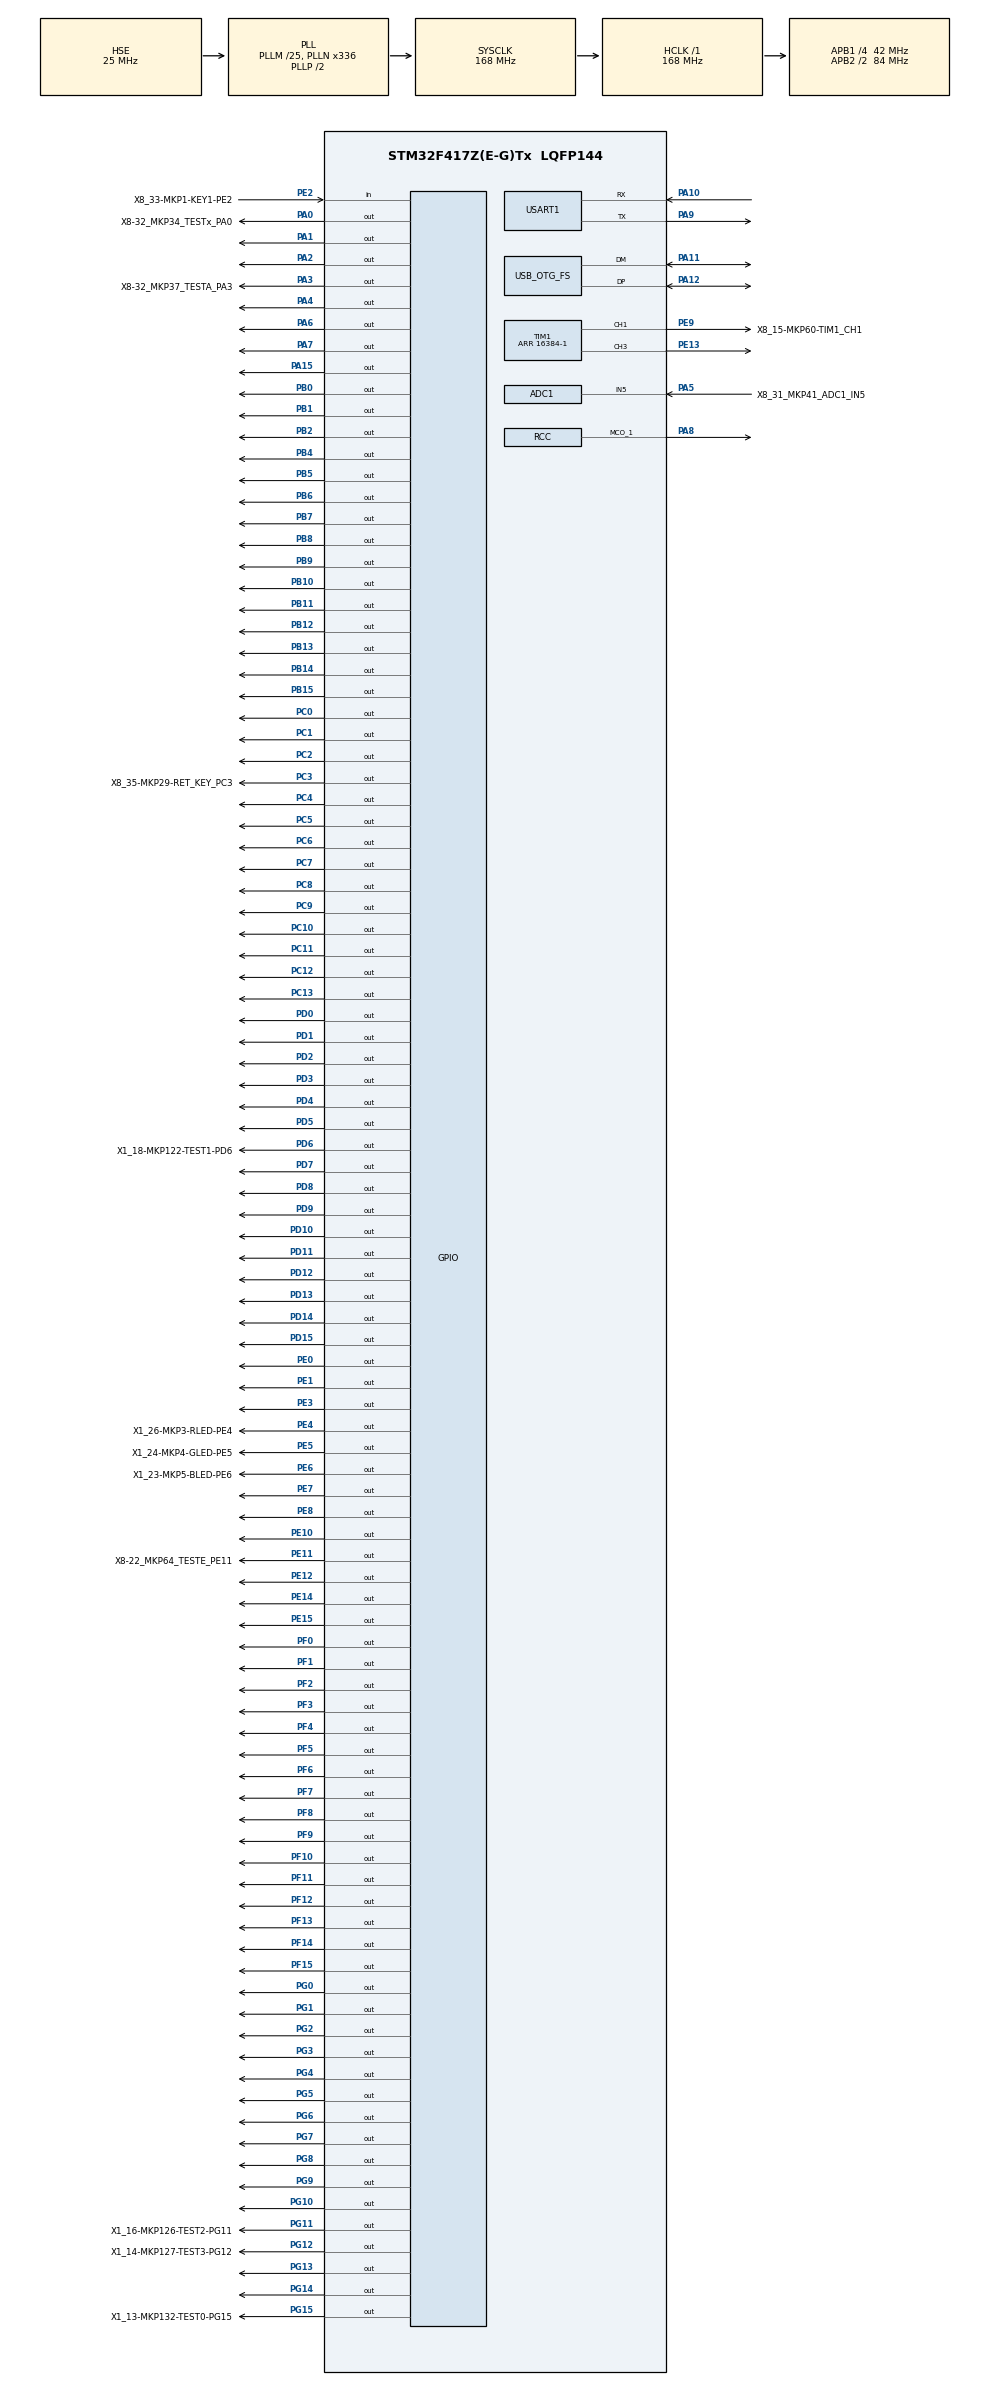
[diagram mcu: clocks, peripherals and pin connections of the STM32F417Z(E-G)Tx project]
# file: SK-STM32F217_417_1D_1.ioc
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ADC1.Channel-2\#ChannelRegularConversion=ADC_CHANNEL_5
ADC1.Channel-3\#ChannelRegularConversion=ADC_CHANNEL_VREFINT
ADC1.ClockPrescaler=ADC_CLOCK_SYNC_PCLK_DIV6
ADC1.DMAContinuousRequests=ENABLE
ADC1.EOCSelection=ADC_EOC_SEQ_CONV
ADC1.ExternalTrigConv=ADC_EXTERNALTRIGCONV_T2_TRGO
ADC1.NbrOfConversion=2
ADC1.NbrOfConversionFlag=1
ADC1.Rank-2\#ChannelRegularConversion=1
ADC1.Rank-3\#ChannelRegularConversion=2
ADC1.SamplingTime-2\#ChannelRegularConversion=ADC_SAMPLETIME_144CYCLES
ADC1.SamplingTime-3\#ChannelRegularConversion=ADC_SAMPLETIME_144CYCLES
ADC1.ScanConvMode=ENABLE
ADC1.master=1
Dma.ADC1.1.Direction=DMA_PERIPH_TO_MEMORY
Dma.ADC1.1.FIFOMode=DMA_FIFOMODE_DISABLE
Dma.ADC1.1.Instance=DMA2_Stream0
Dma.ADC1.1.MemDataAlignment=DMA_MDATAALIGN_HALFWORD
Dma.ADC1.1.MemInc=DMA_MINC_ENABLE
Dma.ADC1.1.Mode=DMA_NORMAL
Dma.ADC1.1.PeriphDataAlignment=DMA_PDATAALIGN_HALFWORD
Dma.ADC1.1.PeriphInc=DMA_PINC_DISABLE
Dma.ADC1.1.Priority=DMA_PRIORITY_MEDIUM
Dma.Request0=USART1_TX
Dma.Request1=ADC1
Dma.USART1_TX.0.Direction=DMA_MEMORY_TO_PERIPH
Dma.USART1_TX.0.FIFOMode=DMA_FIFOMODE_DISABLE
Dma.USART1_TX.0.Instance=DMA2_Stream7
Dma.USART1_TX.0.MemDataAlignment=DMA_MDATAALIGN_BYTE
Dma.USART1_TX.0.MemInc=DMA_MINC_ENABLE
Dma.USART1_TX.0.Mode=DMA_NORMAL
Dma.USART1_TX.0.PeriphDataAlignment=DMA_PDATAALIGN_BYTE
Dma.USART1_TX.0.PeriphInc=DMA_PINC_DISABLE
Dma.USART1_TX.0.Priority=DMA_PRIORITY_LOW
IWDG.Prescaler=IWDG_PRESCALER_128
Mcu.Family=STM32F4
Mcu.Name=STM32F417Z(E-G)Tx
Mcu.Package=LQFP144
NVIC.ADC_IRQn=true\:0\:0\:false\:false\:true\:true\:true\:true
NVIC.DMA2_Stream0_IRQn=true\:0\:0\:false\:false\:true\:false\:true\:true
NVIC.DMA2_Stream7_IRQn=true\:0\:0\:false\:false\:true\:false\:true\:true
NVIC.OTG_FS_IRQn=true\:4\:0\:true\:false\:true\:true\:true\:true
NVIC.PriorityGroup=NVIC_PRIORITYGROUP_4
NVIC.TIM1_UP_TIM10_IRQn=true\:0\:0\:false\:false\:true\:true\:true\:true
NVIC.TIM2_IRQn=true\:0\:0\:false\:false\:true\:true\:true\:true
NVIC.USART1_IRQn=true\:3\:0\:true\:false\:true\:true\:true\:true
PA0-WKUP.GPIO_Label=X8-32_MKP34_TESTx_PA0
PA0-WKUP.Signal=GPIO_Output
PA1.Signal=GPIO_Output
PA10.Mode=Asynchronous
PA10.Signal=USART1_RX
PA11.Mode=Device_Only
PA11.Signal=USB_OTG_FS_DM
PA12.Mode=Device_Only
PA12.Signal=USB_OTG_FS_DP
PA13.Mode=Trace_Asynchronous_SW
PA13.Signal=SYS_JTMS-SWDIO
PA14.Mode=Trace_Asynchronous_SW
PA14.Signal=SYS_JTCK-SWCLK
PA15.Signal=GPIO_Output
PA2.Signal=GPIO_Output
PA3.GPIO_Label=X8-32_MKP37_TESTA_PA3
PA3.Signal=GPIO_Output
PA4.Signal=GPIO_Output
PA5.GPIO_Label=X8_31_MKP41_ADC1_IN5
PA5.Signal=ADCx_IN5
PA6.Signal=GPIO_Output
PA7.Signal=GPIO_Output
PA8.Mode=Clock-out-1
PA8.Signal=RCC_MCO_1
PA9.Mode=Asynchronous
PA9.Signal=USART1_TX
PB0.Signal=GPIO_Output
PB1.Signal=GPIO_Output
PB10.Signal=GPIO_Output
PB11.Signal=GPIO_Output
PB12.Signal=GPIO_Output
PB13.Signal=GPIO_Output
PB14.Signal=GPIO_Output
PB15.Signal=GPIO_Output
PB2.Signal=GPIO_Output
PB3.Mode=Trace_Asynchronous_SW
PB3.Signal=SYS_JTDO-SWO
PB4.Signal=GPIO_Output
PB5.Signal=GPIO_Output
PB6.Signal=GPIO_Output
PB7.Signal=GPIO_Output
PB8.Signal=GPIO_Output
PB9.Signal=GPIO_Output
PC0.Signal=GPIO_Output
PC1.Signal=GPIO_Output
PC10.Signal=GPIO_Output
PC11.Signal=GPIO_Output
PC12.Signal=GPIO_Output
PC13-ANTI_TAMP.Signal=GPIO_Output
PC14-OSC32_IN.Mode=LSE-External-Oscillator
PC14-OSC32_IN.Signal=RCC_OSC32_IN
PC15-OSC32_OUT.Mode=LSE-External-Oscillator
PC15-OSC32_OUT.Signal=RCC_OSC32_OUT
PC2.Signal=GPIO_Output
PC3.GPIO_Label=X8_35-MKP29-RET_KEY_PC3
PC3.Signal=GPIO_Output
PC4.Signal=GPIO_Output
PC5.Signal=GPIO_Output
PC6.Signal=GPIO_Output
PC7.Signal=GPIO_Output
PC8.Signal=GPIO_Output
PC9.Signal=GPIO_Output
PD0.Signal=GPIO_Output
PD1.Signal=GPIO_Output
PD10.Signal=GPIO_Output
PD11.Signal=GPIO_Output
PD12.Signal=GPIO_Output
PD13.Signal=GPIO_Output
PD14.Signal=GPIO_Output
PD15.Signal=GPIO_Output
PD2.Signal=GPIO_Output
PD3.Signal=GPIO_Output
PD4.Signal=GPIO_Output
PD5.Signal=GPIO_Output
PD6.GPIO_Label=X1_18-MKP122-TEST1-PD6
PD6.GPIO_Speed=GPIO_SPEED_FREQ_VERY_HIGH
PD6.Signal=GPIO_Output
PD7.Signal=GPIO_Output
PD8.Signal=GPIO_Output
PD9.Signal=GPIO_Output
PE0.Signal=GPIO_Output
PE1.Signal=GPIO_Output
PE10.Signal=GPIO_Output
PE11.GPIO_Label=X8-22_MKP64_TESTE_PE11
PE11.Signal=GPIO_Output
PE12.Signal=GPIO_Output
PE13.Signal=S_TIM1_CH3
PE14.Signal=GPIO_Output
PE15.Signal=GPIO_Output
PE2.GPIO_Label=X8_33-MKP1-KEY1-PE2
PE2.GPIO_PuPd=GPIO_PULLUP
PE2.Signal=GPIO_Input
PE3.Signal=GPIO_Output
PE4.GPIO_Label=X1_26-MKP3-RLED-PE4
PE4.PinState=GPIO_PIN_SET
PE4.Signal=GPIO_Output
PE5.GPIO_Label=X1_24-MKP4-GLED-PE5
PE5.PinState=GPIO_PIN_SET
PE5.Signal=GPIO_Output
PE6.GPIO_Label=X1_23-MKP5-BLED-PE6
PE6.PinState=GPIO_PIN_SET
PE6.Signal=GPIO_Output
PE7.Signal=GPIO_Output
PE8.Signal=GPIO_Output
PE9.GPIO_Label=X8_15-MKP60-TIM1_CH1
PE9.GPIO_Speed=GPIO_SPEED_FREQ_VERY_HIGH
PE9.Signal=S_TIM1_CH1
PF0.Signal=GPIO_Output
PF1.Signal=GPIO_Output
PF10.Signal=GPIO_Output
PF11.Signal=GPIO_Output
PF12.Signal=GPIO_Output
PF13.Signal=GPIO_Output
PF14.Signal=GPIO_Output
PF15.Signal=GPIO_Output
PF2.Signal=GPIO_Output
PF3.Signal=GPIO_Output
PF4.Signal=GPIO_Output
PF5.Signal=GPIO_Output
PF6.Signal=GPIO_Output
PF7.Signal=GPIO_Output
PF8.Signal=GPIO_Output
PF9.Signal=GPIO_Output
PG0.Signal=GPIO_Output
PG1.Signal=GPIO_Output
PG10.Signal=GPIO_Output
PG11.GPIO_Label=X1_16-MKP126-TEST2-PG11
PG11.GPIO_Speed=GPIO_SPEED_FREQ_VERY_HIGH
PG11.Signal=GPIO_Output
PG12.GPIO_Label=X1_14-MKP127-TEST3-PG12
PG12.GPIO_Speed=GPIO_SPEED_FREQ_VERY_HIGH
PG12.Signal=GPIO_Output
PG13.Signal=GPIO_Output
PG14.Signal=GPIO_Output
PG15.GPIO_Label=X1_13-MKP132-TEST0-PG15
PG15.GPIO_Speed=GPIO_SPEED_FREQ_VERY_HIGH
PG15.Signal=GPIO_Output
PG2.Signal=GPIO_Output
PG3.Signal=GPIO_Output
PG4.Signal=GPIO_Output
PG5.Signal=GPIO_Output
PG6.Signal=GPIO_Output
PG7.Signal=GPIO_Output
PG8.Signal=GPIO_Output
PG9.Signal=GPIO_Output
PH0-OSC_IN.Mode=HSE-External-Oscillator
PH0-OSC_IN.Signal=RCC_OSC_IN
PH1-OSC_OUT.Mode=HSE-External-Oscillator
PH1-OSC_OUT.Signal=RCC_OSC_OUT
ProjectManager.HeapSize=0x2000
ProjectManager.StackSize=0x2000
ProjectManager.TargetToolchain=MDK-ARM V5.32
RCC.48MHZClocksFreq_Value=48000000
RCC.AHBFreq_Value=168000000
RCC.APB1CLKDivider=RCC_HCLK_DIV4
RCC.APB1Freq_Value=42000000
RCC.APB1TimFreq_Value=84000000
RCC.APB2CLKDivider=RCC_HCLK_DIV2
RCC.APB2Freq_Value=84000000
RCC.APB2TimFreq_Value=168000000
RCC.CortexFreq_Value=168000000
RCC.HCLKFreq_Value=168000000
RCC.HSE_VALUE=25000000
RCC.HSI_VALUE=16000000
RCC.PLLM=25
RCC.PLLN=336
RCC.PLLQ=7
RCC.RCC_MCO1Source=RCC_MCO1SOURCE_HSE
RCC.RCC_RTC_Clock_Source=RCC_RTCCLKSOURCE_LSE
RCC.RCC_RTC_Clock_SourceVirtual=RCC_RTCCLKSOURCE_LSE
RCC.SYSCLKFreq_VALUE=168000000
RCC.SYSCLKSource=RCC_SYSCLKSOURCE_PLLCLK
RCC.VCOOutputFreq_Value=336000000
SH.ADCx_IN5.0=ADC1_IN5,IN5
SH.S_TIM1_CH1.0=TIM1_CH1,PWM Generation1 CH1
SH.S_TIM1_CH3.0=TIM1_CH3,Output Compare3 CH3
TIM1.AutoReloadPreload=TIM_AUTORELOAD_PRELOAD_ENABLE
TIM1.AutomaticOutput=TIM_AUTOMATICOUTPUT_DISABLE
TIM1.Channel-Output\ Compare3\ CH3=TIM_CHANNEL_3
TIM1.Channel-PWM\ Generation1\ CH1=TIM_CHANNEL_1
TIM1.ClockDivision=TIM_CLOCKDIVISION_DIV1
TIM1.OC1Preload_PWM=DISABLE
TIM1.OCMode_PWM-PWM\ Generation1\ CH1=TIM_OCMODE_PWM1
TIM1.OCPolarity_1=TIM_OCPOLARITY_LOW
TIM1.Period=16384-1
TIM1.Pulse-PWM\ Generation1\ CH1=1000
TIM2.AutoReloadPreload=TIM_AUTORELOAD_PRELOAD_ENABLE
TIM2.ClockDivision=TIM_CLOCKDIVISION_DIV1
TIM2.Period=199
TIM2.Prescaler=41
TIM2.TIM_MasterOutputTrigger=TIM_TRGO_UPDATE
USART1.VirtualMode=VM_ASYNC
USB_DEVICE.CLASS_NAME_FS=CDC
USB_DEVICE.VirtualMode-CDC_FS=Cdc
USB_DEVICE.VirtualModeFS=Cdc_FS
USB_OTG_FS.VirtualMode=Device_Only
VP_ADC1_Vref_Input.Mode=IN-Vrefint
VP_IWDG_VS_IWDG.Mode=IWDG_Activate
VP_TIM1_VS_ClockSourceINT.Mode=Internal
VP_TIM2_VS_ClockSourceINT.Mode=Internal
VP_USB_DEVICE_VS_USB_DEVICE_CDC_FS.Mode=CDC_FS
board=custom

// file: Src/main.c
/* USER CODE BEGIN Header */
/**
  ******************************************************************************
  * @file           : main.c
  * @brief          : Main program body
  ******************************************************************************
  * @attention
  *
  * Copyright (c) 2026 STMicroelectronics.
  * All rights reserved.
  *
  * This software is licensed under terms that can be found in the LICENSE file
  * in the root directory of this software component.
  * If no LICENSE file comes with this software, it is provided AS-IS.
  *
  ******************************************************************************
  */
/* USER CODE END Header */
#include "main.h"
#include "adc.h"
#include "dma.h"
#include "iwdg.h"
#include "tim.h"
#include "usart.h"
#include "usb_device.h"
#include "gpio.h"

/* USER CODE BEGIN Includes */
#include "usbd_cdc_if.h"

/* USER CODE END Includes */

/* USER CODE BEGIN PV */
volatile uint32_t AdcBuffConvCntr = 0;
static uint16_t AdcDblBuff[2][CONV_FRAME_COUNT*CHANNEL_COUNT];
static TickType_t AdcFrameNextTime = 0;
static uint32_t AdcLastBuffSumm = 0;
static uint32_t AdcLastRefSumm = 0;

static bool fAdcReady = true, fAdcDataReady = false;

static uint32_t OutAcc = 0;
static uint32_t OutRefAcc = 0;

static char OutTextBuf[128];
static TickType_t OutDataNextTime = 0;

static TickType_t LedBlinkNextTime = 0;

extern volatile TickType_t Tim1mS;
extern DMA_HandleTypeDef hdma_adc1;
extern TIM_HandleTypeDef htim2;
/* USER CODE END PV */

void SystemClock_Config(void);

/* USER CODE BEGIN 0 */
//******************************************************************************
// User functions
//------------------------------------------------------------------------------
// For debug printf
int fputc(int ch, FILE *f)
{
  UNUSED(f);

  ITM_SendChar(ch);
  return(ch);
}
//------------------------------------------------------------------------------
__weak TickType_t Get1mSTickCount64(void)
{
  TickType_t res;
  __disable_interrupt();
  res = Tim1mS;
  __enable_interrupt();
  return res;
}
//------------------------------------------------------------------------------
__weak void sDelay(TickType_t Delay)
{
  Delay += Get1mSTickCount64();

  while(Get1mSTickCount64() > Delay) {
    __watchdog_reset();
  }
}

//******************************************************************************
//------------------------------------------------------------------------------
// Interrupt DMA Transfer Complete callback
static void DMA_AdcFrameCplt(DMA_HandleTypeDef *_hdma)
{
  if(&hdma_adc1 == _hdma) {
    TEST1ON();
    AdcBuffConvCntr++;
    fAdcReady = true;
    HAL_ADC_Stop_DMA(&hadc1);
    TEST1OFF();
  }
}
//------------------------------------------------------------------------------
void HAL_TIM_PeriodElapsedCallback(TIM_HandleTypeDef *htim)
{
  /* Prevent unused argument(s) compilation warning */
  UNUSED(htim);

  /* NOTE : This function should not be modified, when the callback is needed,
            the HAL_TIM_PeriodElapsedCallback could be implemented in the user file
   */
  if(&htim1 == htim) {
    TEST3ON();
    TEST3OFF();
  }
  if(&htim2 == htim) {
    TEST2ON();
    TEST2OFF();
  }
}
//------------------------------------------------------------------------------
void HAL_ADC_ConvCpltCallback(ADC_HandleTypeDef *hadc)
{
  /* Prevent unused argument(s) compilation warning */
  UNUSED(hadc);
  /* NOTE : This function Should not be modified, when the callback is needed,
            the HAL_ADC_ConvCpltCallback could be implemented in the user file
  */
  if(&hadc1 == hadc) {
    TEST3ON();
    AdcBuffConvCntr++;
    fAdcReady = true;
    HAL_ADC_Stop_DMA(&hadc1);
    TEST3OFF();
  }
}
//------------------------------------------------------------------------------

static int AdcBuffSumm(const uint16_t *Buff, int Count, uint16_t ErrTreshold, uint32_t *Summ, uint32_t *SummRef)
{
  int ret = 0, Avg;

  *SummRef = *Summ = 0;

  Avg = (Buff[0] + Buff[CHANNEL_COUNT] + 1) >> 1;
  if(ErrTreshold > abs((int)Avg - (int)Buff[0]))
    *Summ = Buff[0];
  else {
    *Summ = Avg; ret--;
  }
  Avg = (Buff[1] + Buff[1+CHANNEL_COUNT] + 1) >> 1;
  if(ErrTreshold > abs((int)Avg - (int)Buff[1]))
    *SummRef = Buff[1];
  else {
    *SummRef = Avg; ret--;
  }

  for(int i=1;i<Count-1;i++)
  {

    Avg = (Buff[(i-1)*CHANNEL_COUNT] + Buff[(i+1)*CHANNEL_COUNT] + 1) >> 1;
    if(ErrTreshold > abs((int)Avg - (int)Buff[i*CHANNEL_COUNT]))
      *Summ += Buff[i*CHANNEL_COUNT];
    else {
      *Summ += Avg; ret--;
    }
    Avg = (Buff[(i-1)*CHANNEL_COUNT+1] + Buff[(i+1)*CHANNEL_COUNT+1] + 1) >> 1;
    if(ErrTreshold > abs((int)Avg - (int)Buff[i*CHANNEL_COUNT+1]))
      *SummRef += Buff[i*CHANNEL_COUNT+1];
    else {
      *SummRef += Avg; ret--;
    }
  }

  Avg = (Buff[(Count-2)*CHANNEL_COUNT] + Buff[(Count-1)*CHANNEL_COUNT] + 1) >> 1;
  if(ErrTreshold > abs((int)Avg - (int)Buff[(Count-1)*CHANNEL_COUNT]))
    *Summ += Buff[Count-1];
  else {
    *Summ = Avg; ret--;
  }
  Avg = (Buff[(Count-2)*CHANNEL_COUNT+1] + Buff[(Count-1)*CHANNEL_COUNT+1] + 1) >> 1;
  if(ErrTreshold > abs((int)Avg - (int)Buff[(Count-1)*CHANNEL_COUNT+1]))
    *SummRef += Buff[Count-1];
  else {
    *SummRef = Avg; ret--;
  }

  // Умножаем сумму на коэффициент оверсэмплинга
  // K = (1<<CONV_FRAME_OVERS_POW)=(1<<2)=4)
  *Summ <<= CONV_FRAME_OVERS_POW; // Oversampling multipler
  *SummRef <<= CONV_FRAME_OVERS_POW; // Oversampling multipler

  return ret;
}
//------------------------------------------------------------------------------
static void SetPwmOut(uint32_t Value) {
  // Устанавливаем новое значение ШИМ
  TIM_OC_InitTypeDef pwmConfigOC;
  pwmConfigOC.OCMode = TIM_OCMODE_PWM1;
  pwmConfigOC.Pulse = Value;
  pwmConfigOC.OCPolarity = TIM_OCPOLARITY_HIGH;
  pwmConfigOC.OCNPolarity = TIM_OCNPOLARITY_HIGH;
  pwmConfigOC.OCFastMode = TIM_OCFAST_DISABLE;
  pwmConfigOC.OCIdleState = TIM_OCIDLESTATE_RESET;
  pwmConfigOC.OCNIdleState = TIM_OCNIDLESTATE_RESET;
  if (HAL_TIM_PWM_ConfigChannel(&htim1, &pwmConfigOC, PWM_TIM1_CHANNEL) != HAL_OK)
  {
    LOG_ERROR("%s :: HAL_TIM_PWM_ConfigChannel - fail\r\n", __func__);
    Error_Handler();
  }
  // Hack! For decrease setup time (two wariants))
  /* Set the Capture Compare Register value
  htim1.Instance->CCR1 = Value; */
  /* Set the Capture Compare Register value
  __HAL_TIM_SetCompare(&htim1, PWM_TIM1_CHANNEL, Value); */

}
//------------------------------------------------------------------------------
static HAL_StatusTypeDef OutTextVal(int AdcOutAvg, int AdcVrefAvg) {
  HAL_StatusTypeDef status;

  sprintf(OutTextBuf, "AdcVin = %d mV\r\n", (int)ADC2MV(AdcOutAvg));

  status = HAL_UART_Transmit_DMA(&huart1, (uint8_t*)OutTextBuf, strlen(OutTextBuf));
  status |= CDC_Transmit_FS((uint8_t*)OutTextBuf, strlen(OutTextBuf));
  // 13 uS
  LOG_PRINTF("AdcVin = %d mV, AdcVref = %d\r\n", (int)ADC2MV(AdcOutAvg), (int)ADC2MV(AdcVrefAvg));

  return status;
}

//******************************************************************************
/* USER CODE END 0 */

int main(void)
{

  /* USER CODE BEGIN 1 */
  HAL_StatusTypeDef status;
  /* USER CODE END 1 */

  /* MCU Configuration--------------------------------------------------------*/

  /* Reset of all peripherals, Initializes the Flash interface and the Systick. */
  HAL_Init();

  /* Configure the system clock */
  SystemClock_Config();

  /* Initialize all configured peripherals */
  MX_GPIO_Init();
  MX_DMA_Init();
  MX_IWDG_Init();
  MX_USART1_UART_Init();
  MX_USB_DEVICE_Init();
  MX_ADC1_Init();
  MX_TIM1_Init();
  MX_TIM2_Init();
  /* USER CODE BEGIN 2 */
  if (HAL_DMA_RegisterCallback(&hdma_adc1, HAL_DMA_XFER_CPLT_CB_ID, DMA_AdcFrameCplt) != HAL_OK)
  {
    Error_Handler();
  }

  memset(AdcDblBuff, 0, sizeof(AdcDblBuff));

  HAL_ADC_Stop_DMA(&hadc1);
  HAL_ADC_Stop(&hadc1);

  HAL_TIM_Base_Start_IT(&htim1);
  HAL_TIM_Base_Start_IT(&htim2);

  //__HAL_RCC_GPIOA_RELEASE_RESET();

  TESTAOFF();
  TESTEOFF();

  //SetPwmOut(1000);
  status = HAL_TIM_PWM_Start(&htim1, TIM_CHANNEL_1);
  __HAL_TIM_SetCompare(&htim1, PWM_TIM1_CHANNEL, 1000);
  status = HAL_TIM_PWM_Start(&htim1, TIM_CHANNEL_1);
  status = HAL_TIM_OC_Start(&htim1, TIM_CHANNEL_2);

  Sleep(150);
  /* USER CODE END 2 */

  /* Infinite loop */
  /* USER CODE BEGIN WHILE */
  while (1)
  {
    __watchdog_reset();

    if((fAdcReady)&&(Get1mSTickCount() >= AdcFrameNextTime))
    {
      TEST1ON();
      AdcFrameNextTime = Get1mSTickCount() + CONV_FRAME_TIME_mS;

      fAdcReady = false;

      fAdcDataReady = true;

      status = HAL_ADC_Start_DMA(&hadc1, (uint32_t*)AdcDblBuff[AdcBuffConvCntr & 0x1],
                                 CONV_FRAME_COUNT*CHANNEL_COUNT);
      if(HAL_OK != status) {
      	LOG_ERROR("%s :: HAL_ADC_Start_DMA -fail, status = %d\r\n", __func__, (int)status);
      }
      TEST1OFF();
    }
    else
    {
      if((Get1mSTickCount() >= OutDataNextTime))
      { // 29 uS
        OutDataNextTime = Get1mSTickCount() + OUT_VALUE_TIME_mS;

        int AdcOutAvg = (OutAcc + (OUT_VALUE_COUNT >> 1) + 1) / (OUT_VALUE_COUNT);
        int AdcRefAvg = (OutRefAcc + (OUT_VALUE_COUNT >> 1) + 1) / (OUT_VALUE_COUNT);
        OutRefAcc = OutAcc = 0;

        OutTextVal(AdcOutAvg, AdcRefAvg);
        GLEDTGL();
      }
    }

    if(fAdcDataReady)
    {
      fAdcDataReady = false;
      // Обработика полученного буфера
      TESTATGL();

      // Рассчитываем полную сумму по буферу
      AdcBuffSumm(AdcDblBuff[(AdcBuffConvCntr & 0x1) ^ 0x1], CONV_FRAME_COUNT,
                             ADC_MAX_ERR_THD, &AdcLastBuffSumm, &AdcLastRefSumm);
      // Получаем среднеарифметическое по буферу, для округления добавляенм половину количества
      uint32_t ValueAvg = (AdcLastBuffSumm + (CONV_FRAME_COUNT >> 1) + 1) / CONV_FRAME_COUNT;
      uint32_t ValueRefAvg = (AdcLastRefSumm + (CONV_FRAME_COUNT >> 1) + 1) / CONV_FRAME_COUNT;

      OutAcc += ValueAvg;
      OutRefAcc += ValueRefAvg;

      // Устанавливаем новое значение ШИМ
      SetPwmOut(ValueAvg);
      TESTETGL();
    }

    if(Get1mSTickCount() >= LedBlinkNextTime)
    {
      LedBlinkNextTime = Get1mSTickCount() + LED_BLINK_TIME_mS;
      RLEDTGL();
    }
    /* USER CODE END WHILE */

  }
}

void SystemClock_Config(void)
{
  RCC_OscInitTypeDef RCC_OscInitStruct = {0};
  RCC_ClkInitTypeDef RCC_ClkInitStruct = {0};

  /** Configure the main internal regulator output voltage
  */
  __HAL_RCC_PWR_CLK_ENABLE();
  __HAL_PWR_VOLTAGESCALING_CONFIG(PWR_REGULATOR_VOLTAGE_SCALE1);

  /** Initializes the RCC Oscillators according to the specified parameters
  * in the RCC_OscInitTypeDef structure.
  */
  RCC_OscInitStruct.OscillatorType = RCC_OSCILLATORTYPE_LSI|RCC_OSCILLATORTYPE_HSE;
  RCC_OscInitStruct.HSEState = RCC_HSE_ON;
  RCC_OscInitStruct.LSIState = RCC_LSI_ON;
  RCC_OscInitStruct.PLL.PLLState = RCC_PLL_ON;
  RCC_OscInitStruct.PLL.PLLSource = RCC_PLLSOURCE_HSE;
  RCC_OscInitStruct.PLL.PLLM = 25;
  RCC_OscInitStruct.PLL.PLLN = 336;
  RCC_OscInitStruct.PLL.PLLP = RCC_PLLP_DIV2;
  RCC_OscInitStruct.PLL.PLLQ = 7;
  if (HAL_RCC_OscConfig(&RCC_OscInitStruct) != HAL_OK)
  {
    Error_Handler();
  }

  /** Initializes the CPU, AHB and APB buses clocks
  */
  RCC_ClkInitStruct.ClockType = RCC_CLOCKTYPE_HCLK|RCC_CLOCKTYPE_SYSCLK
                              |RCC_CLOCKTYPE_PCLK1|RCC_CLOCKTYPE_PCLK2;
  RCC_ClkInitStruct.SYSCLKSource = RCC_SYSCLKSOURCE_PLLCLK;
  RCC_ClkInitStruct.AHBCLKDivider = RCC_SYSCLK_DIV1;
  RCC_ClkInitStruct.APB1CLKDivider = RCC_HCLK_DIV4;
  RCC_ClkInitStruct.APB2CLKDivider = RCC_HCLK_DIV2;

  if (HAL_RCC_ClockConfig(&RCC_ClkInitStruct, FLASH_LATENCY_5) != HAL_OK)
  {
    Error_Handler();
  }
  HAL_RCC_MCOConfig(RCC_MCO1, RCC_MCO1SOURCE_HSE, RCC_MCODIV_1);
}

void Error_Handler(void)
{
  __disable_irq();
  while (1)
  {
  }
}
#ifdef USE_FULL_ASSERT
/**
  * @brief  Reports the name of the source file and the source line number
  *         where the assert_param error has occurred.
  * @param  file: pointer to the source file name
  * @param  line: assert_param error line source number
  * @retval None
  */
void assert_failed(uint8_t *file, uint32_t line)
{
  /* USER CODE BEGIN 6 */
  UNUSED(file);
  UNUSED(line);
  /* User can add his own implementation to report the file name and line number,
     ex: printf("Wrong parameters value: file %s on line %d\r\n", file, line) */
  /* USER CODE END 6 */
}
#endif /* USE_FULL_ASSERT */
